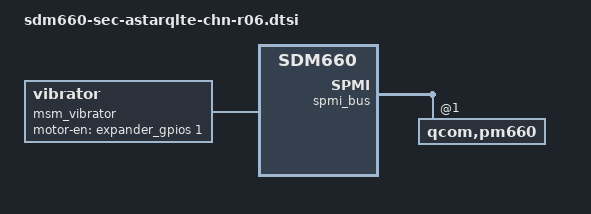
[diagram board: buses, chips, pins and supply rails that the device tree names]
/*
 * Copyright (c) 2017, The Linux Foundation. All rights reserved.
 *
 * This program is free software; you can redistribute it and/or modify
 * it under the terms of the GNU General Public License version 2 and
 * only version 2 as published by the Free Software Foundation.
 *
 * This program is distributed in the hope that it will be useful,
 * but WITHOUT ANY WARRANTY; without even the implied warranty of
 * MERCHANTABILITY or FITNESS FOR A PARTICULAR PURPOSE.  See the
 * GNU General Public License for more details.
 */




#include "sdm660-sec-astarqlte-common.dtsi"

&soc {
	msm_vibrator {
		compatible = "vibrator";
		motor-vdd_type = <0>; /* 0: gpio, 1: pmic */
		motor-en = <&expander_gpios 1 0x0>;
	};
};

&spmi_bus {
	qcom,pm660@1 {
	        pm660_haptics: qcom,haptic@c000 {
                        status = "disabled";
	        };
	};
};

